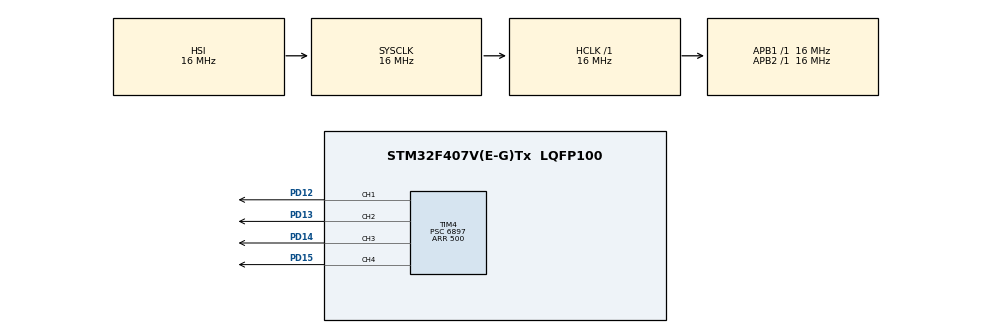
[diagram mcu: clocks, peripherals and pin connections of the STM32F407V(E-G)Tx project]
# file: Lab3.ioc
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Mcu.Family=STM32F4
Mcu.Name=STM32F407V(E-G)Tx
Mcu.Package=LQFP100
NVIC.PriorityGroup=NVIC_PRIORITYGROUP_4
PD12.Signal=S_TIM4_CH1
PD13.Signal=S_TIM4_CH2
PD14.Signal=S_TIM4_CH3
PD15.Signal=S_TIM4_CH4
ProjectManager.HeapSize=0x200
ProjectManager.StackSize=0x400
ProjectManager.TargetToolchain=STM32CubeIDE
RCC.AHBFreq_Value=16000000
RCC.APB1Freq_Value=16000000
RCC.APB2Freq_Value=16000000
RCC.CortexFreq_Value=16000000
RCC.HSE_VALUE=25000000
RCC.HSI_VALUE=16000000
RCC.LSE_VALUE=32768
RCC.SYSCLKFreq_VALUE=16000000
RCC.VCOOutputFreq_Value=192000000
SH.S_TIM4_CH1.0=TIM4_CH1,PWM Generation1 CH1
SH.S_TIM4_CH2.0=TIM4_CH2,PWM Generation2 CH2
SH.S_TIM4_CH3.0=TIM4_CH3,PWM Generation3 CH3
SH.S_TIM4_CH4.0=TIM4_CH4,PWM Generation4 CH4
TIM4.AutoReloadPreload=TIM_AUTORELOAD_PRELOAD_ENABLE
TIM4.Channel-PWM\ Generation1\ CH1=TIM_CHANNEL_1
TIM4.Channel-PWM\ Generation2\ CH2=TIM_CHANNEL_2
TIM4.Channel-PWM\ Generation3\ CH3=TIM_CHANNEL_3
TIM4.Channel-PWM\ Generation4\ CH4=TIM_CHANNEL_4
TIM4.CounterMode=TIM_COUNTERMODE_DOWN
TIM4.Period=500
TIM4.Prescaler=6897
VP_TIM4_VS_ClockSourceINT.Mode=Internal
board=custom

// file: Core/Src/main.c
/* USER CODE BEGIN Header */
/**
  ******************************************************************************
  * @file           : main.c
  * @brief          : Main program body
  ******************************************************************************
  * @attention
  *
  * Copyright (c) 2023 STMicroelectronics.
  * All rights reserved.
  *
  * This software is licensed under terms that can be found in the LICENSE file
  * in the root directory of this software component.
  * If no LICENSE file comes with this software, it is provided AS-IS.
  *
  ******************************************************************************
  */
/* USER CODE END Header */
#include "main.h"

TIM_HandleTypeDef htim4;

void SystemClock_Config(void);
static void MX_GPIO_Init(void);
static void MX_TIM4_Init(void);

int main(void)
{

  /* MCU Configuration--------------------------------------------------------*/

  /* Reset of all peripherals, Initializes the Flash interface and the Systick. */
  HAL_Init();

  /* Configure the system clock */
  SystemClock_Config();

  /* Initialize all configured peripherals */
  MX_GPIO_Init();
  MX_TIM4_Init();
  /* USER CODE BEGIN 2 */

  HAL_TIM_PWM_Start(&htim4, TIM_CHANNEL_1);
  HAL_TIM_PWM_Start(&htim4, TIM_CHANNEL_2);
  HAL_TIM_PWM_Start(&htim4, TIM_CHANNEL_3);
  HAL_TIM_PWM_Start(&htim4, TIM_CHANNEL_4);

  TIM4->CCR1=435; // GREEN - 87%
  TIM4->CCR2=265; // ORANGE - 53%
  TIM4->CCR3=390; // RED - 78%
  TIM4->CCR4=250; // BLUE - 50%

  /* USER CODE END 2 */

  /* Infinite loop */
  while (1)
  {

  }
}

void SystemClock_Config(void)
{
  RCC_OscInitTypeDef RCC_OscInitStruct = {0};
  RCC_ClkInitTypeDef RCC_ClkInitStruct = {0};

  /** Configure the main internal regulator output voltage
  */
  __HAL_RCC_PWR_CLK_ENABLE();
  __HAL_PWR_VOLTAGESCALING_CONFIG(PWR_REGULATOR_VOLTAGE_SCALE1);

  /** Initializes the RCC Oscillators according to the specified parameters
  * in the RCC_OscInitTypeDef structure.
  */
  RCC_OscInitStruct.OscillatorType = RCC_OSCILLATORTYPE_HSI;
  RCC_OscInitStruct.HSIState = RCC_HSI_ON;
  RCC_OscInitStruct.HSICalibrationValue = RCC_HSICALIBRATION_DEFAULT;
  RCC_OscInitStruct.PLL.PLLState = RCC_PLL_NONE;
  if (HAL_RCC_OscConfig(&RCC_OscInitStruct) != HAL_OK)
  {
    Error_Handler();
  }

  /** Initializes the CPU, AHB and APB buses clocks
  */
  RCC_ClkInitStruct.ClockType = RCC_CLOCKTYPE_HCLK|RCC_CLOCKTYPE_SYSCLK
                              |RCC_CLOCKTYPE_PCLK1|RCC_CLOCKTYPE_PCLK2;
  RCC_ClkInitStruct.SYSCLKSource = RCC_SYSCLKSOURCE_HSI;
  RCC_ClkInitStruct.AHBCLKDivider = RCC_SYSCLK_DIV1;
  RCC_ClkInitStruct.APB1CLKDivider = RCC_HCLK_DIV1;
  RCC_ClkInitStruct.APB2CLKDivider = RCC_HCLK_DIV1;

  if (HAL_RCC_ClockConfig(&RCC_ClkInitStruct, FLASH_LATENCY_0) != HAL_OK)
  {
    Error_Handler();
  }
}

static void MX_TIM4_Init(void)
{

  TIM_ClockConfigTypeDef sClockSourceConfig = {0};
  TIM_MasterConfigTypeDef sMasterConfig = {0};
  TIM_OC_InitTypeDef sConfigOC = {0};

  htim4.Instance = TIM4;
  htim4.Init.Prescaler = 6897;
  htim4.Init.CounterMode = TIM_COUNTERMODE_DOWN;
  htim4.Init.Period = 500;
  htim4.Init.ClockDivision = TIM_CLOCKDIVISION_DIV1;
  htim4.Init.AutoReloadPreload = TIM_AUTORELOAD_PRELOAD_ENABLE;
  if (HAL_TIM_Base_Init(&htim4) != HAL_OK)
  {
    Error_Handler();
  }
  sClockSourceConfig.ClockSource = TIM_CLOCKSOURCE_INTERNAL;
  if (HAL_TIM_ConfigClockSource(&htim4, &sClockSourceConfig) != HAL_OK)
  {
    Error_Handler();
  }
  if (HAL_TIM_PWM_Init(&htim4) != HAL_OK)
  {
    Error_Handler();
  }
  sMasterConfig.MasterOutputTrigger = TIM_TRGO_RESET;
  sMasterConfig.MasterSlaveMode = TIM_MASTERSLAVEMODE_DISABLE;
  if (HAL_TIMEx_MasterConfigSynchronization(&htim4, &sMasterConfig) != HAL_OK)
  {
    Error_Handler();
  }
  sConfigOC.OCMode = TIM_OCMODE_PWM1;
  sConfigOC.Pulse = 0;
  sConfigOC.OCPolarity = TIM_OCPOLARITY_HIGH;
  sConfigOC.OCFastMode = TIM_OCFAST_DISABLE;
  if (HAL_TIM_PWM_ConfigChannel(&htim4, &sConfigOC, TIM_CHANNEL_1) != HAL_OK)
  {
    Error_Handler();
  }
  if (HAL_TIM_PWM_ConfigChannel(&htim4, &sConfigOC, TIM_CHANNEL_2) != HAL_OK)
  {
    Error_Handler();
  }
  if (HAL_TIM_PWM_ConfigChannel(&htim4, &sConfigOC, TIM_CHANNEL_3) != HAL_OK)
  {
    Error_Handler();
  }
  if (HAL_TIM_PWM_ConfigChannel(&htim4, &sConfigOC, TIM_CHANNEL_4) != HAL_OK)
  {
    Error_Handler();
  }
  HAL_TIM_MspPostInit(&htim4);

}

static void MX_GPIO_Init(void)
{

  /* GPIO Ports Clock Enable */
  __HAL_RCC_GPIOD_CLK_ENABLE();

}

void Error_Handler(void)
{
  __disable_irq();
  while (1)
  {
  }
}
